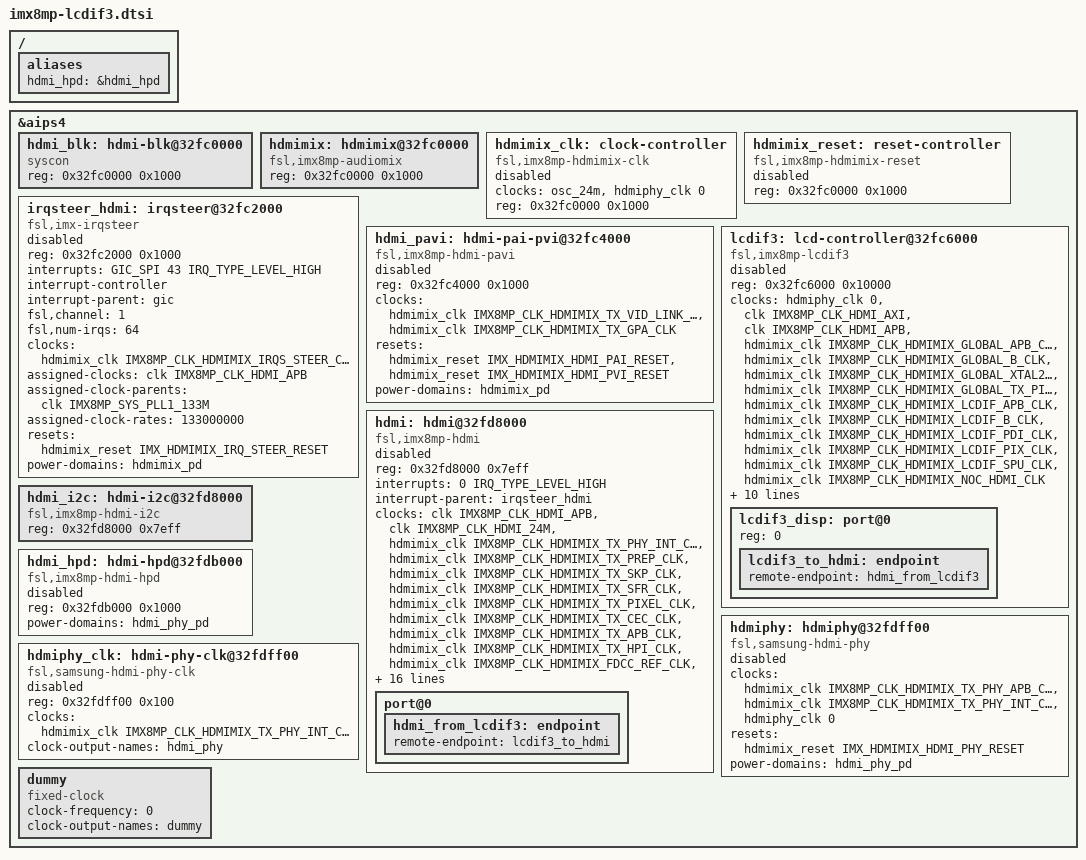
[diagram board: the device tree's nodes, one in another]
#include <dt-bindings/clock/imx8mp-clock1.h>
#include <dt-bindings/reset/imx-hdmimix-reset.h>

/{ 
	aliases {
		hdmi_hpd = &hdmi_hpd;
	};
};

&aips4 {
	/* TODO for HDMI PHY power on */
	hdmi_blk: hdmi-blk@32fc0000 {
		compatible = "syscon";
		reg = <0x32fc0000 0x1000>;
	};

	hdmimix: hdmimix@32fc0000 {
		compatible = "fsl,imx8mp-audiomix", "fsl,imx8mp-hdmimix";
		reg = <0x32fc0000 0x1000>;
	};

	hdmimix_clk: clock-controller {
		compatible = "fsl,imx8mp-hdmimix-clk", "syscon";
		#clock-cells = <1>;
		clocks = <&osc_24m>, <&hdmiphy_clk 0>;
		clock-names = "osc_24m", "hdmi_phy";
		reg = <0x32fc0000 0x1000>;
		status = "disabled";
	};

	hdmimix_reset: reset-controller {
		compatible = "fsl,imx8mp-hdmimix-reset";
		reg = <0x32fc0000 0x1000>;
		#reset-cells = <1>;
		status = "disabled";
	};

	irqsteer_hdmi: irqsteer@32fc2000 {
		compatible = "fsl,imx-irqsteer";
		reg = <0x32fc2000 0x1000>;
		interrupts = <GIC_SPI 43 IRQ_TYPE_LEVEL_HIGH>;
		interrupt-controller;
		interrupt-parent = <&gic>;
		#interrupt-cells = <1>;
		fsl,channel = <1>;
		fsl,num-irqs = <64>;
		clocks = <&hdmimix_clk IMX8MP_CLK_HDMIMIX_IRQS_STEER_CLK>;
		clock-names = "ipg";
		assigned-clocks = <&clk IMX8MP_CLK_HDMI_APB>;
		assigned-clock-parents = <&clk IMX8MP_SYS_PLL1_133M>;
		assigned-clock-rates = <133000000>;
		resets = <&hdmimix_reset IMX_HDMIMIX_IRQ_STEER_RESET>;
		power-domains = <&hdmimix_pd>;
		status = "disabled";
	};

	hdmi_pavi: hdmi-pai-pvi@32fc4000 {
		#phy-cells = <1>;
		compatible = "fsl,imx8mp-hdmi-pavi";
		reg = <0x32fc4000 0x1000>;
		clocks = <&hdmimix_clk IMX8MP_CLK_HDMIMIX_TX_VID_LINK_PIX_CLK>,
				<&hdmimix_clk IMX8MP_CLK_HDMIMIX_TX_GPA_CLK>;
		clock-names = "pvi_clk", "pai_clk";
		resets = <&hdmimix_reset IMX_HDMIMIX_HDMI_PAI_RESET>,
				<&hdmimix_reset IMX_HDMIMIX_HDMI_PVI_RESET>;
		reset-names = "pai_rst", "pvi_rst";
		power-domains = <&hdmimix_pd>;
		status = "disabled";
	};

	lcdif3: lcd-controller@32fc6000 {
		#address-cells = <1>;
		#size-cells = <0>;
		compatible = "fsl,imx8mp-lcdif3";
		reg = <0x32fc6000 0x10000>;
		clocks = <&hdmiphy_clk 0>,
				<&clk IMX8MP_CLK_HDMI_AXI>,
				<&clk IMX8MP_CLK_HDMI_APB>,
				<&hdmimix_clk IMX8MP_CLK_HDMIMIX_GLOBAL_APB_CLK>,
				<&hdmimix_clk IMX8MP_CLK_HDMIMIX_GLOBAL_B_CLK>,
				<&hdmimix_clk IMX8MP_CLK_HDMIMIX_GLOBAL_XTAL24M_CLK>,
				<&hdmimix_clk IMX8MP_CLK_HDMIMIX_GLOBAL_TX_PIX_CLK>,
				<&hdmimix_clk IMX8MP_CLK_HDMIMIX_LCDIF_APB_CLK>,
				<&hdmimix_clk IMX8MP_CLK_HDMIMIX_LCDIF_B_CLK>,
				<&hdmimix_clk IMX8MP_CLK_HDMIMIX_LCDIF_PDI_CLK>,
				<&hdmimix_clk IMX8MP_CLK_HDMIMIX_LCDIF_PIX_CLK>,
				<&hdmimix_clk IMX8MP_CLK_HDMIMIX_LCDIF_SPU_CLK>,
				<&hdmimix_clk IMX8MP_CLK_HDMIMIX_NOC_HDMI_CLK>;
		clock-names = "pix", "disp-axi", "disp-apb",
					"mix_apb","mix_axi", "xtl_24m", "mix_pix", "lcdif_apb",
					"lcdif_axi", "lcdif_pdi", "lcdif_pix", "lcdif_spu",
					"noc_hdmi";
		assigned-clocks =  <&clk IMX8MP_CLK_HDMI_AXI>,
						<&clk IMX8MP_CLK_HDMI_APB>;
		assigned-clock-parents = <&clk IMX8MP_SYS_PLL2_500M>,
					 <&clk IMX8MP_SYS_PLL1_133M>;
		assigned-clock-rates = <500000000>, <133000000>;
		interrupts = <8 IRQ_TYPE_LEVEL_HIGH>;
		interrupt-parent = <&irqsteer_hdmi>;
		resets = <&hdmimix_reset IMX_HDMIMIX_LCDIF_RESET>;
		power-domains = <&hdmimix_pd>;
		status = "disabled";

		lcdif3_disp: port@0 {
			reg = <0>;

			lcdif3_to_hdmi: endpoint {
				remote-endpoint = <&hdmi_from_lcdif3>;
			};
		};
	};

	hdmi: hdmi@32fd8000 {
		compatible = "fsl,imx8mp-hdmi";
		reg = <0x32fd8000 0x7eff>;
		interrupts = <0 IRQ_TYPE_LEVEL_HIGH>;
		interrupt-parent = <&irqsteer_hdmi>;
		clocks = <&clk IMX8MP_CLK_HDMI_APB>,
				<&clk IMX8MP_CLK_HDMI_24M>,
				<&hdmimix_clk IMX8MP_CLK_HDMIMIX_TX_PHY_INT_CLK>,
				<&hdmimix_clk IMX8MP_CLK_HDMIMIX_TX_PREP_CLK>,
				<&hdmimix_clk IMX8MP_CLK_HDMIMIX_TX_SKP_CLK>,
				<&hdmimix_clk IMX8MP_CLK_HDMIMIX_TX_SFR_CLK>,
				<&hdmimix_clk IMX8MP_CLK_HDMIMIX_TX_PIXEL_CLK>,
				<&hdmimix_clk IMX8MP_CLK_HDMIMIX_TX_CEC_CLK>,
				<&hdmimix_clk IMX8MP_CLK_HDMIMIX_TX_APB_CLK>,
				<&hdmimix_clk IMX8MP_CLK_HDMIMIX_TX_HPI_CLK>,
				<&hdmimix_clk IMX8MP_CLK_HDMIMIX_FDCC_REF_CLK>,
				<&hdmimix_clk IMX8MP_CLK_HDMIMIX_TX_PIPE_CLK_SEL>;
		clock-names = "iahb", "isfr", "phy_int", "prep_clk", "skp_clk", "sfr_clk", "pix_clk",
						"cec_clk", "apb_clk", "hpi_clk", "fdcc_ref", "pipe_clk";
		assigned-clocks = <&clk IMX8MP_CLK_HDMI_APB>,
					<&clk IMX8MP_CLK_HDMI_AXI>,
					<&clk IMX8MP_CLK_HDMI_24M>;
		assigned-clock-parents = <&clk IMX8MP_SYS_PLL1_133M>,
					<&clk IMX8MP_SYS_PLL2_500M>,
					<&clk IMX8MP_CLK_24M>;
		assigned-clock-rates = <133000000>, <500000000>, <24000000>;
		ddc-i2c-bus = <&hdmi_i2c>;
		phys = <&hdmiphy>, <&hdmi_pavi 0>, <&hdmi_pavi 1>, <&hdmi_pavi 2>;
		phy-names = "hdmi", "pavi", "pvi", "pai";
		resets = <&hdmimix_reset IMX_HDMIMIX_HDMI_TX_RESET>;
		gpr = <&hdmimix_clk>;
		power-domains = <&hdmi_phy_pd>;
		status = "disabled";

		port@0 {
			hdmi_from_lcdif3: endpoint {
				remote-endpoint = <&lcdif3_to_hdmi>;
			};
		};
	};

	hdmi_i2c: hdmi-i2c@32fd8000 {
		compatible = "fsl,imx8mp-hdmi-i2c";
		reg = <0x32fd8000 0x7eff>;
	};

	hdmi_hpd: hdmi-hpd@32fdb000 {
		compatible = "fsl,imx8mp-hdmi-hpd";
		reg = <0x32fdb000 0x1000>;
		power-domains = <&hdmi_phy_pd>;
		status = "disabled";
	};

	hdmiphy: hdmiphy@32fdff00 {
		compatible = "fsl,samsung-hdmi-phy";
		clocks = <&hdmimix_clk IMX8MP_CLK_HDMIMIX_TX_PHY_APB_CLK>,
				<&hdmimix_clk IMX8MP_CLK_HDMIMIX_TX_PHY_INT_CLK>,
				<&hdmiphy_clk 0>;
		clock-names = "apb", "ref", "hdmi_phy";
		#phy-cells = <0>;
		resets = <&hdmimix_reset IMX_HDMIMIX_HDMI_PHY_RESET>;
		power-domains = <&hdmi_phy_pd>;
		status = "disabled";
	};

	hdmiphy_clk: hdmi-phy-clk@32fdff00 {
		#clock-cells = <1>;
		#size-cells = <0>;
		reg = <0x32fdff00 0x100>;
		compatible = "fsl,samsung-hdmi-phy-clk";
		clocks = <&hdmimix_clk IMX8MP_CLK_HDMIMIX_TX_PHY_INT_CLK>;
		clock-names = "parent";
		clock-output-names = "hdmi_phy";
		status = "disabled";
	};

	dummy: dummy {
		compatible = "fixed-clock";
		#clock-cells = <0>;
		clock-frequency = <0>;
		clock-output-names = "dummy";
	};
};
